VERSION ""

NS_ :

BS_:

BU_: EGS DKG IHKA DME Kombi CAS JBBF Tester ZGW AHM EMF LM ACSM SEC1 EPS ICM_QL DSC FRMFA CVM SM_BFH SM_FA SM_BF FKA HKA EKP GWS Vector__XXX

CM_ "EGS received";

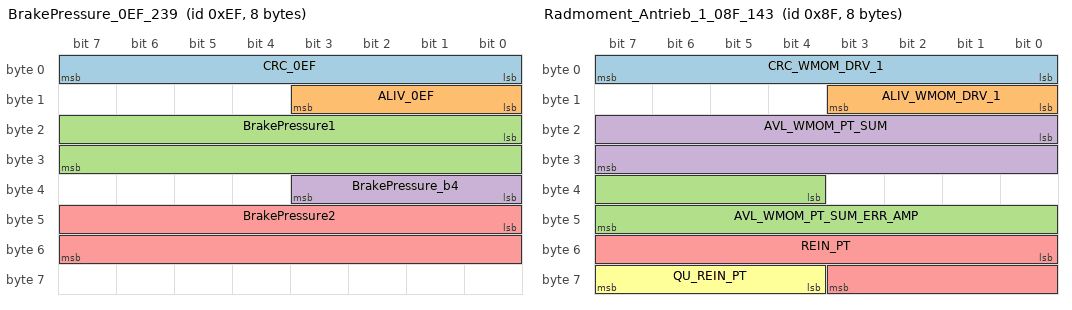
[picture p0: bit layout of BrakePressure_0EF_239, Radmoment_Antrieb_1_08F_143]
BO_ 239 BrakePressure_0EF_239: 8 DSC
 SG_ CRC_0EF : 0|8@1+ (1,0) [0|255] "" Vector__XXX
 SG_ ALIV_0EF : 8|4@1+ (1,0) [0|14] "" Vector__XXX
 SG_ BrakePressure1 : 16|16@1+ (1,0) [0|65535] "" Vector__XXX
 SG_ BrakePressure_b4 : 32|4@1+ (1,0) [0|15] "" Vector__XXX
 SG_ BrakePressure2 : 40|16@1+ (1,0) [0|65535] "" Vector__XXX

BO_ 143 Radmoment_Antrieb_1_08F_143: 8 DME
 SG_ CRC_WMOM_DRV_1 : 0|8@1+ (1,0) [0|255] "" Vector__XXX
 SG_ ALIV_WMOM_DRV_1 : 8|4@1+ (1,0) [0|14] "" Vector__XXX
 SG_ AVL_WMOM_PT_SUM_ERR_AMP : 36|12@1+ (4,0) [0|16000] "Nm" Vector__XXX
 SG_ AVL_WMOM_PT_SUM : 16|16@1+ (1,-32000) [-32000|32000] "Nm" Vector__XXX
 SG_ REIN_PT : 48|12@1+ (0.125,0) [0|511.75] "" Vector__XXX
 SG_ QU_REIN_PT : 60|4@1+ (1,0) [0|15] "" Vector__XXX
